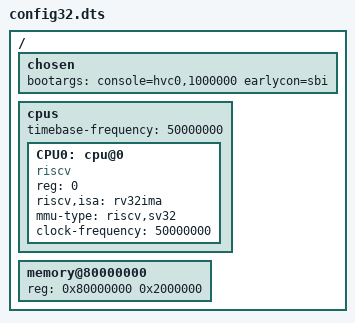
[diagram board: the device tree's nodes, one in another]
// SPDX-License-Identifier: GPL-2.0
// 控制台走 SBI(hvc0)—— 稳定、完整可交互。UART 仍是真 RTL,但内核经 SBI 固件用它。
/dts-v1/;

/ {
  #address-cells = <1>;
  #size-cells = <1>;

  chosen {
      bootargs = "console=hvc0,1000000 earlycon=sbi";
  };

  cpus {
    #address-cells = <1>;
    #size-cells = <0>;
    timebase-frequency = <50000000>;
    CPU0: cpu@0 {
      device_type = "cpu";
      reg = <0>;
      status = "okay";
      compatible = "riscv";
      riscv,isa = "rv32ima";
      mmu-type = "riscv,sv32";
      clock-frequency = <50000000>;
    };
  };

  memory@80000000 {
      device_type = "memory";
      reg = <0x80000000 0x2000000>;
  };
};
